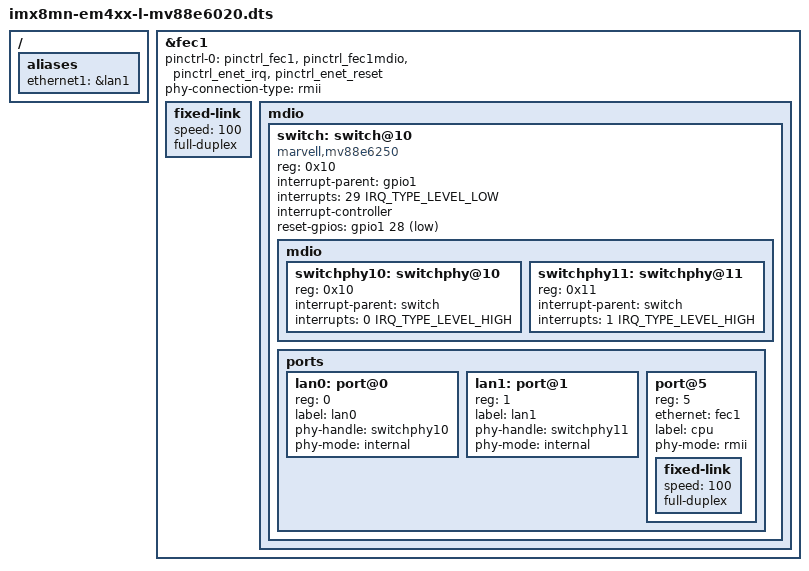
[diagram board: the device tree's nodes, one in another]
// SPDX-License-Identifier: GPL-2.0-or-later
/*
 * Copyright (c) 2023 - 2024 TQ-Systems GmbH <linux@ew.tq-group.com>,
 * D-82229 Seefeld, Germany.
 * Author: Michael Krummsdorf
 */

/dts-v1/;

#include "imx8mn-em4xx.dtsi"

/ {
	aliases {
		ethernet1 = &lan1;
	};
};

&fec1 {
	pinctrl-names = "default";
	pinctrl-0 = <&pinctrl_fec1>,
		    <&pinctrl_fec1mdio>,
		    <&pinctrl_enet_irq>,
		    <&pinctrl_enet_reset>;
	phy-connection-type = "rmii";
	status = "okay";

	fixed-link {
		speed = <100>;
		full-duplex;
	};

	mdio {
		#address-cells = <1>;
		#size-cells = <0>;
		status = "okay";

		switch: switch@10 {
			compatible = "marvell,mv88e6250";
			reg = <0x10>;
			interrupt-parent = <&gpio1>;
			interrupts = <29 IRQ_TYPE_LEVEL_LOW>;
			interrupt-controller;
			#interrupt-cells = <2>;
			reset-gpios = <&gpio1 28 GPIO_ACTIVE_LOW>;

			mdio {
				#address-cells = <1>;
				#size-cells = <0>;

				switchphy10: switchphy@10 {
					reg = <0x10>;
					interrupt-parent = <&switch>;
					interrupts = <0 IRQ_TYPE_LEVEL_HIGH>;
				};

				switchphy11: switchphy@11 {
					reg = <0x11>;
					interrupt-parent = <&switch>;
					interrupts = <1 IRQ_TYPE_LEVEL_HIGH>;
				};
			};

			ports {
				#address-cells = <1>;
				#size-cells = <0>;

				lan0: port@0 {
					reg = <0>;
					label = "lan0";
					phy-handle = <&switchphy10>;
					phy-mode = "internal";
				};

				lan1: port@1 {
					reg = <1>;
					label = "lan1";
					phy-handle = <&switchphy11>;
					phy-mode = "internal";
				};

				port@5 {
					reg = <5>;
					ethernet = <&fec1>;
					label = "cpu";
					phy-mode = "rmii";

					fixed-link {
						speed = <100>;
						full-duplex;
					};
				};
			};
		};
	};
};
